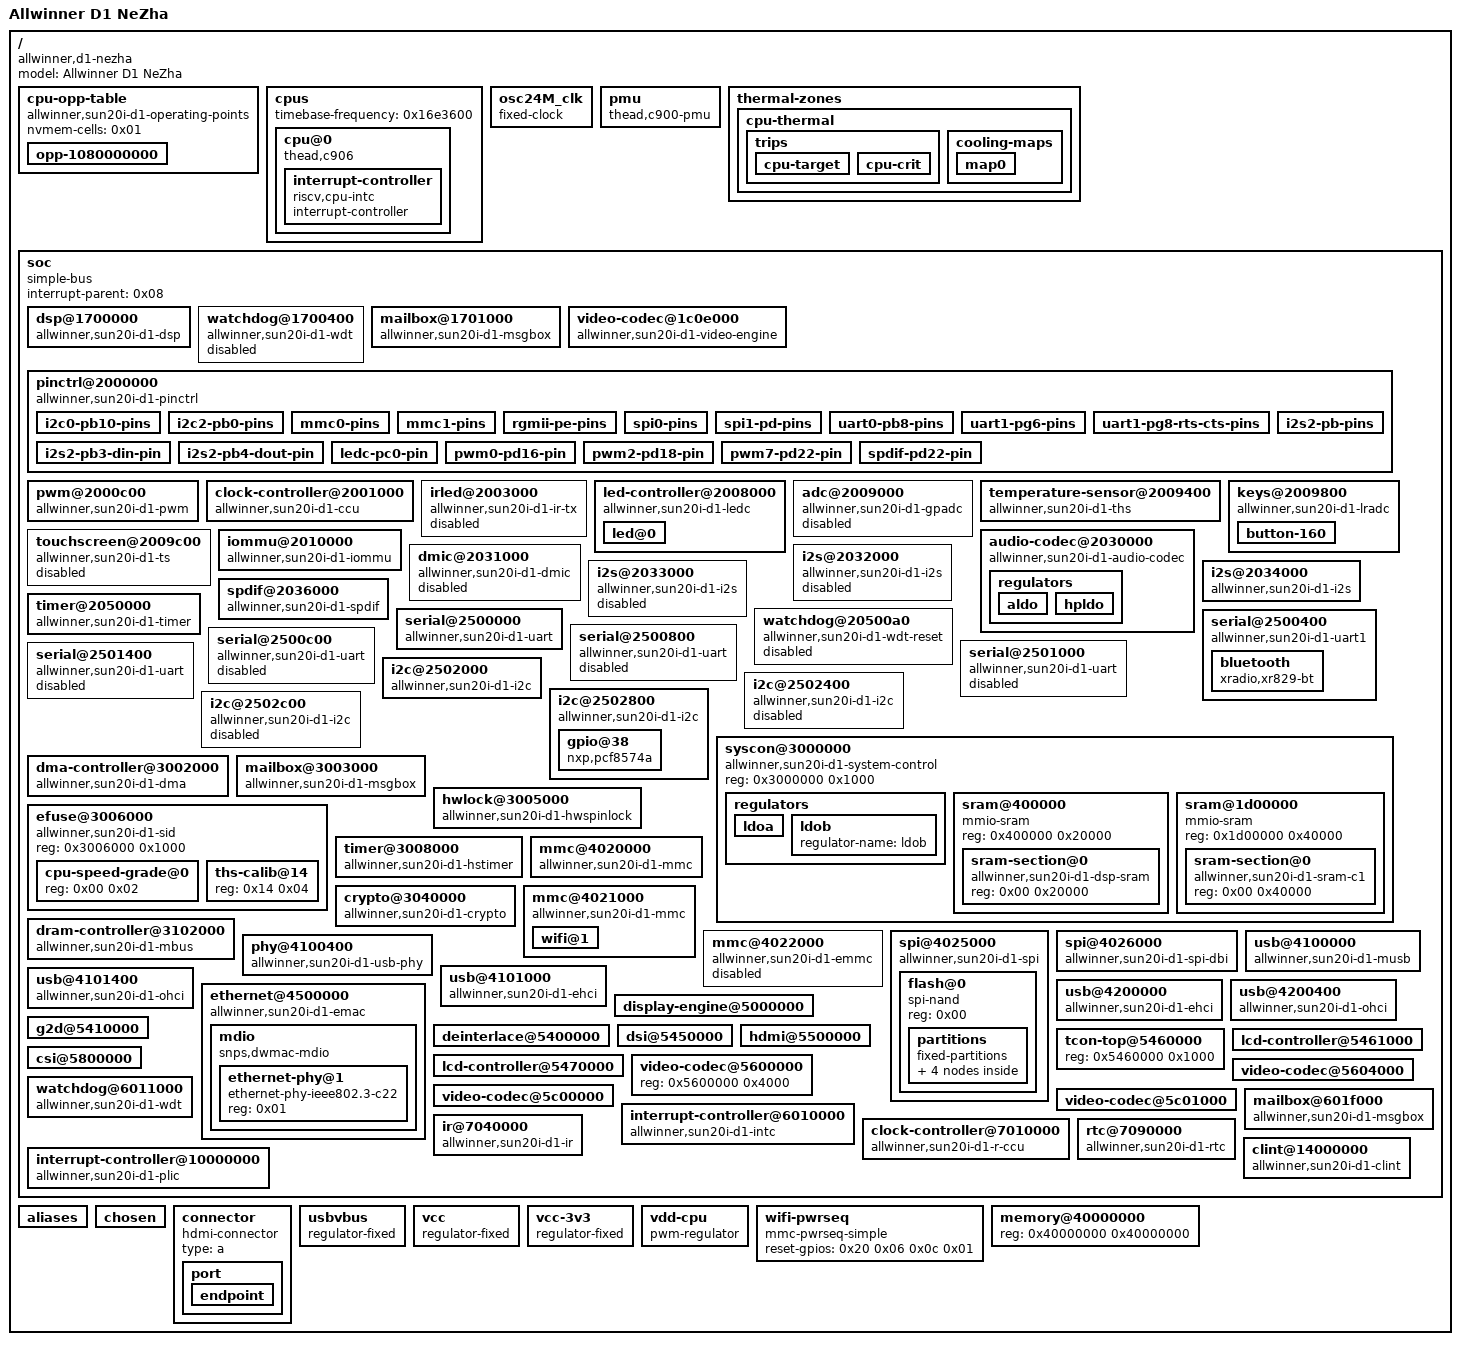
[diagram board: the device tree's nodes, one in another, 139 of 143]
/dts-v1/;

/ {
	#address-cells = <0x01>;
	#size-cells = <0x01>;
	model = "Allwinner D1 NeZha";
	compatible = "allwinner,d1-nezha", "allwinner,sun20i-d1";

	cpu-opp-table {
		compatible = "allwinner,sun20i-d1-operating-points", "allwinner,sun50i-h6-operating-points";
		nvmem-cells = <0x01>;
		phandle = <0x03>;

		opp-1080000000 {
			clock-latency-ns = <0x3b9b0>;
			opp-hz = <0x00 0x3c14dc00>;
			opp-microvolt-speed0 = <0x10c8e0>;
		};
	};

	cpus {
		#address-cells = <0x01>;
		#size-cells = <0x00>;
		timebase-frequency = <0x16e3600>;

		cpu@0 {
			compatible = "thead,c906", "riscv";
			device_type = "cpu";
			reg = <0x00>;
			clocks = <0x02 0x84>;
			clock-frequency = <0x16e3600>;
			#cooling-cells = <0x02>;
			d-cache-block-size = <0x40>;
			d-cache-sets = <0x100>;
			d-cache-size = <0x8000>;
			i-cache-block-size = <0x40>;
			i-cache-sets = <0x80>;
			i-cache-size = <0x8000>;
			mmu-type = "riscv,sv39";
			operating-points-v2 = <0x03>;
			riscv,isa = "rv64imafdc";
			cpu-supply = <0x04>;
			phandle = <0x07>;

			interrupt-controller {
				compatible = "riscv,cpu-intc";
				#address-cells = <0x00>;
				interrupt-controller;
				#interrupt-cells = <0x01>;
				phandle = <0x30>;
			};
		};
	};

	osc24M_clk {
		#clock-cells = <0x00>;
		compatible = "fixed-clock";
		clock-frequency = <0x16e3600>;
		clock-output-names = "osc24M";
		phandle = <0x0c>;
	};

	pmu {
		compatible = "thead,c900-pmu";
	};

	thermal-zones {

		cpu-thermal {
			polling-delay = <0x00>;
			polling-delay-passive = <0x00>;
			thermal-sensors = <0x05 0x00>;

			trips {

				cpu-target {
					hysteresis = <0xbb8>;
					temperature = <0x14c08>;
					type = "passive";
					phandle = <0x06>;
				};

				cpu-crit {
					hysteresis = <0x00>;
					temperature = <0x1adb0>;
					type = "critical";
				};
			};

			cooling-maps {

				map0 {
					trip = <0x06>;
					cooling-device = <0x07 0xffffffff 0xffffffff>;
				};
			};
		};
	};

	soc {
		compatible = "simple-bus";
		#address-cells = <0x01>;
		#size-cells = <0x01>;
		ranges;
		interrupt-parent = <0x08>;

		dsp@1700000 {
			compatible = "allwinner,sun20i-d1-dsp";
			reg = <0x1700000 0x400>;
			reg-names = "cfg";
			clocks = <0x02 0x83 0x02 0x82>;
			clock-names = "cfg", "dsp";
			resets = <0x02 0x3f 0x02 0x40 0x02 0x3e>;
			allwinner,sram = <0x09 0x01>;
			interrupts = <0x88 0x04 0x89 0x04>;
			interrupt-names = "dee", "pfe";
			mboxes = <0x0a 0x01 0x00 0x0b 0x02 0x01>;
			mbox-names = "rx", "tx";
		};

		watchdog@1700400 {
			compatible = "allwinner,sun20i-d1-wdt";
			reg = <0x1700400 0x20>;
			clocks = <0x0c>;
			interrupts = <0x8a 0x04>;
			status = "reserved";
		};

		mailbox@1701000 {
			compatible = "allwinner,sun20i-d1-msgbox";
			reg = <0x1701000 0x1000>;
			clocks = <0x02 0x27>;
			resets = <0x02 0x08>;
			interrupts = <0x8b 0x04 0x8c 0x04>;
			interrupt-names = "rx", "tx";
			#mbox-cells = <0x02>;
			phandle = <0x0b>;
		};

		video-codec@1c0e000 {
			compatible = "allwinner,sun20i-d1-video-engine";
			reg = <0x1c0e000 0x2000>;
			clocks = <0x02 0x24 0x02 0x23 0x02 0x31>;
			clock-names = "ahb", "mod", "ram";
			resets = <0x02 0x05>;
			allwinner,sram = <0x0d 0x01>;
			interconnects = <0x0e 0x04>;
			interconnect-names = "dma-mem";
			interrupts = <0x52 0x04>;
			iommus = <0x0f 0x00>;
		};

		pinctrl@2000000 {
			compatible = "allwinner,sun20i-d1-pinctrl";
			#address-cells = <0x00>;
			reg = <0x2000000 0x800>;
			clocks = <0x02 0x18 0x0c 0x10 0x00>;
			clock-names = "apb", "hosc", "losc";
			gpio-controller;
			#gpio-cells = <0x03>;
			interrupts = <0x55 0x04 0x57 0x04 0x59 0x04 0x5b 0x04 0x5d 0x04 0x5f 0x04>;
			interrupt-names = "pb", "pc", "pd", "pe", "pf", "pg";
			interrupt-controller;
			#interrupt-cells = <0x03>;
			vcc-pa-supply = <0x11>;
			vcc-pb-supply = <0x11>;
			vcc-pc-supply = <0x11>;
			vcc-pd-supply = <0x11>;
			vcc-pe-supply = <0x11>;
			vcc-pf-supply = <0x11>;
			vcc-pg-supply = <0x11>;
			phandle = <0x20>;

			i2c0-pb10-pins {
				pins = "PB10", "PB11";
				function = "i2c0";
				phandle = <0x21>;
			};

			i2c2-pb0-pins {
				pins = "PB0", "PB1";
				function = "i2c2";
				phandle = <0x22>;
			};

			mmc0-pins {
				pins = "PF0", "PF1", "PF2", "PF3", "PF4", "PF5";
				function = "mmc0";
				phandle = <0x23>;
			};

			mmc1-pins {
				pins = "PG0", "PG1", "PG2", "PG3", "PG4", "PG5";
				function = "mmc1";
				phandle = <0x25>;
			};

			rgmii-pe-pins {
				pins = "PE0", "PE1", "PE2", "PE3", "PE4", "PE5", "PE6", "PE7", "PE8", "PE9", "PE11", "PE12", "PE13", "PE14", "PE15";
				function = "emac";
				phandle = <0x2c>;
			};

			spi0-pins {
				pins = "PC2", "PC3", "PC4", "PC5", "PC6", "PC7";
				function = "spi0";
				phandle = <0x26>;
			};

			spi1-pd-pins {
				pins = "PD10", "PD11", "PD12", "PD13", "PD14", "PD15";
				function = "spi1";
				phandle = <0x27>;
			};

			uart0-pb8-pins {
				pins = "PB8", "PB9";
				function = "uart0";
				phandle = <0x1d>;
			};

			uart1-pg6-pins {
				pins = "PG6", "PG7";
				function = "uart1";
				phandle = <0x1e>;
			};

			uart1-pg8-rts-cts-pins {
				pins = "PG8", "PG9";
				function = "uart1";
				phandle = <0x1f>;
			};

			i2s2-pb-pins {
				pins = "PB5", "PB6", "PB7";
				function = "i2s2";
				phandle = <0x19>;
			};

			i2s2-pb3-din-pin {
				pins = "PB3";
				function = "i2s2_din";
				phandle = <0x1a>;
			};

			i2s2-pb4-dout-pin {
				pins = "PB4";
				function = "i2s2_dout";
				phandle = <0x1b>;
			};

			ledc-pc0-pin {
				pins = "PC0";
				function = "ledc";
				phandle = <0x15>;
			};

			pwm0-pd16-pin {
				pins = "PD16";
				function = "pwm";
				phandle = <0x12>;
			};

			pwm2-pd18-pin {
				pins = "PD18";
				function = "pwm";
				phandle = <0x13>;
			};

			pwm7-pd22-pin {
				pins = "PD22";
				function = "pwm";
			};

			spdif-pd22-pin {
				pins = "PD22";
				function = "spdif";
				phandle = <0x1c>;
			};
		};

		pwm@2000c00 {
			compatible = "allwinner,sun20i-d1-pwm";
			reg = <0x2000c00 0x400>;
			clocks = <0x02 0x2d 0x0c>;
			clock-names = "bus", "mod";
			resets = <0x02 0x0d>;
			interrupts = <0x22 0x04>;
			#pwm-cells = <0x03>;
			status = "okay";
			pinctrl-0 = <0x12 0x13>;
			pinctrl-names = "default";
			phandle = <0x31>;
		};

		clock-controller@2001000 {
			compatible = "allwinner,sun20i-d1-ccu";
			reg = <0x2001000 0x1000>;
			clocks = <0x0c 0x10 0x00 0x10 0x02>;
			clock-names = "hosc", "losc", "iosc";
			#clock-cells = <0x01>;
			#reset-cells = <0x01>;
			phandle = <0x02>;
		};

		irled@2003000 {
			compatible = "allwinner,sun20i-d1-ir-tx";
			reg = <0x2003000 0x400>;
			clocks = <0x02 0x4f 0x0c 0x02 0x4e>;
			clock-names = "bus", "pclk", "mclk";
			resets = <0x02 0x1f>;
			dmas = <0x14 0x0d>;
			dma-names = "tx";
			interrupts = <0x23 0x04>;
			status = "disabled";
		};

		led-controller@2008000 {
			compatible = "allwinner,sun20i-d1-ledc", "allwinner,sun50i-r329-ledc";
			reg = <0x2008000 0x400>;
			#address-cells = <0x01>;
			#size-cells = <0x00>;
			clocks = <0x02 0x7b 0x02 0x7a>;
			clock-names = "bus", "mod";
			resets = <0x02 0x3b>;
			dmas = <0x14 0x2a>;
			dma-names = "tx";
			interrupts = <0x24 0x04>;
			status = "okay";
			pinctrl-0 = <0x15>;
			pinctrl-names = "default";

			led@0 {
				reg = <0x00>;
				color = <0x09>;
				function = "indicator";
			};
		};

		adc@2009000 {
			compatible = "allwinner,sun20i-d1-gpadc";
			reg = <0x2009000 0x400>;
			clocks = <0x02 0x50>;
			resets = <0x02 0x20>;
			dmas = <0x14 0x0c>;
			dma-names = "rx";
			interrupts = <0x49 0x04>;
			status = "disabled";
		};

		temperature-sensor@2009400 {
			compatible = "allwinner,sun20i-d1-ths";
			reg = <0x2009400 0x400>;
			clocks = <0x02 0x51 0x0c>;
			clock-names = "bus", "mod";
			resets = <0x02 0x21>;
			interrupts = <0x4a 0x04>;
			nvmem-cells = <0x16>;
			nvmem-cell-names = "calibration";
			#thermal-sensor-cells = <0x00>;
			vref-supply = <0x17>;
			phandle = <0x05>;
		};

		keys@2009800 {
			compatible = "allwinner,sun20i-d1-lradc", "allwinner,sun50i-r329-lradc";
			reg = <0x2009800 0x400>;
			clocks = <0x02 0x68>;
			resets = <0x02 0x2f>;
			interrupts = <0x4d 0x04>;
			status = "okay";
			vref-supply = <0x17>;
			wakeup-source;

			button-160 {
				label = "OK";
				linux,code = <0x160>;
				channel = <0x00>;
				voltage = <0x27100>;
			};
		};

		touchscreen@2009c00 {
			compatible = "allwinner,sun20i-d1-ts";
			reg = <0x2009c00 0x400>;
			clocks = <0x02 0x80 0x02 0x7f>;
			clock-names = "bus", "mod";
			resets = <0x02 0x3d>;
			dmas = <0x14 0x0d>;
			dma-names = "rx";
			interrupts = <0x4e 0x04>;
			status = "disabled";
		};

		iommu@2010000 {
			compatible = "allwinner,sun20i-d1-iommu";
			reg = <0x2010000 0x10000>;
			clocks = <0x02 0x2e>;
			interrupts = <0x50 0x04>;
			#iommu-cells = <0x01>;
			phandle = <0x0f>;
		};

		audio-codec@2030000 {
			compatible = "allwinner,sun20i-d1-audio-codec";
			reg = <0x2030000 0x1000>;
			clocks = <0x02 0x60 0x02 0x5f 0x02 0x5e 0x0c 0x10 0x00>;
			clock-names = "bus", "adc", "dac", "hosc", "losc";
			resets = <0x02 0x27>;
			dmas = <0x14 0x07 0x14 0x07>;
			dma-names = "rx", "tx";
			interrupts = <0x29 0x04>;
			#sound-dai-cells = <0x00>;
			status = "okay";
			allwinner,routing = "Headphone Jack", "HPOUTL", "Headphone Jack", "HPOUTR", "LINEINL", "HPOUTL", "LINEINR", "HPOUTR", "MICIN3", "Headset Microphone", "Headset Microphone", "HBIAS";
			allwinner,widgets = "Microphone", "Headset Microphone", "Headphone", "Headphone Jack";
			avcc-supply = <0x17>;
			hpvcc-supply = <0x18>;
			vdd33-supply = <0x11>;

			regulators {

				aldo {
					regulator-name = "aldo";
					regulator-min-microvolt = <0x1b7740>;
					regulator-max-microvolt = <0x1b7740>;
					vdd33-supply = <0x11>;
					phandle = <0x17>;
				};

				hpldo {
					regulator-name = "hpldo";
					regulator-min-microvolt = <0x1b7740>;
					regulator-max-microvolt = <0x1b7740>;
					hpldoin-supply = <0x11>;
					phandle = <0x18>;
				};
			};
		};

		dmic@2031000 {
			compatible = "allwinner,sun20i-d1-dmic";
			reg = <0x2031000 0x400>;
			clocks = <0x02 0x5d 0x02 0x5c>;
			clock-names = "bus", "mod";
			resets = <0x02 0x26>;
			dmas = <0x14 0x08>;
			dma-names = "rx";
			interrupts = <0x28 0x04>;
			#sound-dai-cells = <0x00>;
			status = "disabled";
		};

		i2s@2032000 {
			compatible = "allwinner,sun20i-d1-i2s";
			reg = <0x2032000 0x1000>;
			clocks = <0x02 0x56 0x02 0x52>;
			clock-names = "apb", "mod";
			resets = <0x02 0x22>;
			dmas = <0x14 0x03 0x14 0x03>;
			dma-names = "rx", "tx";
			interrupts = <0x2a 0x04>;
			#sound-dai-cells = <0x00>;
			status = "disabled";
		};

		i2s@2033000 {
			compatible = "allwinner,sun20i-d1-i2s";
			reg = <0x2033000 0x1000>;
			clocks = <0x02 0x57 0x02 0x53>;
			clock-names = "apb", "mod";
			resets = <0x02 0x23>;
			dmas = <0x14 0x04 0x14 0x04>;
			dma-names = "rx", "tx";
			interrupts = <0x2b 0x04>;
			#sound-dai-cells = <0x00>;
			status = "disabled";
		};

		i2s@2034000 {
			compatible = "allwinner,sun20i-d1-i2s";
			reg = <0x2034000 0x1000>;
			clocks = <0x02 0x58 0x02 0x54>;
			clock-names = "apb", "mod";
			resets = <0x02 0x24>;
			dmas = <0x14 0x05 0x14 0x05>;
			dma-names = "rx", "tx";
			interrupts = <0x2c 0x04>;
			#sound-dai-cells = <0x00>;
			status = "okay";
			pinctrl-0 = <0x19 0x1a 0x1b>;
			pinctrl-names = "default";
		};

		spdif@2036000 {
			compatible = "allwinner,sun20i-d1-spdif";
			reg = <0x2036000 0x400>;
			clocks = <0x02 0x5b 0x02 0x5a 0x02 0x59>;
			clock-names = "apb", "rx", "tx";
			resets = <0x02 0x25>;
			dmas = <0x14 0x02 0x14 0x02>;
			dma-names = "rx", "tx";
			interrupts = <0x27 0x04>;
			#sound-dai-cells = <0x00>;
			status = "okay";
			pinctrl-0 = <0x1c>;
			pinctrl-names = "default";
		};

		timer@2050000 {
			compatible = "allwinner,sun20i-d1-timer", "allwinner,sun8i-a23-timer";
			reg = <0x2050000 0xa0>;
			clocks = <0x0c>;
			interrupts = <0x4b 0x04 0x4c 0x04>;
		};

		watchdog@20500a0 {
			compatible = "allwinner,sun20i-d1-wdt-reset", "allwinner,sun20i-d1-wdt";
			reg = <0x20500a0 0x20>;
			clocks = <0x0c>;
			interrupts = <0x4f 0x04>;
			status = "reserved";
		};

		serial@2500000 {
			compatible = "allwinner,sun20i-d1-uart", "snps,dw-apb-uart";
			reg = <0x2500000 0x400>;
			reg-io-width = <0x04>;
			reg-shift = <0x02>;
			clocks = <0x02 0x3e>;
			resets = <0x02 0x12>;
			dmas = <0x14 0x0e 0x14 0x0e>;
			dma-names = "rx", "tx";
			fifo-size = <0x40>;
			interrupts = <0x12 0x04>;
			status = "okay";
			pinctrl-0 = <0x1d>;
			pinctrl-names = "default";
		};

		serial@2500400 {
			compatible = "allwinner,sun20i-d1-uart1", "allwinner,sun20i-d1-uart", "snps,dw-apb-uart";
			reg = <0x2500400 0x400>;
			reg-io-width = <0x04>;
			reg-shift = <0x02>;
			clocks = <0x02 0x3f>;
			resets = <0x02 0x13>;
			dmas = <0x14 0x0f 0x14 0x0f>;
			dma-names = "rx", "tx";
			fifo-size = <0x100>;
			interrupts = <0x13 0x04>;
			status = "okay";
			pinctrl-0 = <0x1e 0x1f>;
			pinctrl-names = "default";

			bluetooth {
				compatible = "xradio,xr829-bt";
				device-wakeup-gpios = <0x20 0x06 0x10 0x01>;
				interrupts-extended = <0x20 0x06 0x11 0x08>;
				interrupt-names = "wakeup";
				reset-gpios = <0x20 0x06 0x12 0x01>;
			};
		};

		serial@2500800 {
			compatible = "allwinner,sun20i-d1-uart", "snps,dw-apb-uart";
			reg = <0x2500800 0x400>;
			reg-io-width = <0x04>;
			reg-shift = <0x02>;
			clocks = <0x02 0x40>;
			resets = <0x02 0x14>;
			dmas = <0x14 0x10 0x14 0x10>;
			dma-names = "rx", "tx";
			fifo-size = <0x100>;
			interrupts = <0x14 0x04>;
			status = "disabled";
		};

		serial@2500c00 {
			compatible = "allwinner,sun20i-d1-uart", "snps,dw-apb-uart";
			reg = <0x2500c00 0x400>;
			reg-io-width = <0x04>;
			reg-shift = <0x02>;
			clocks = <0x02 0x41>;
			resets = <0x02 0x15>;
			dmas = <0x14 0x11 0x14 0x11>;
			dma-names = "rx", "tx";
			fifo-size = <0x100>;
			interrupts = <0x15 0x04>;
			status = "disabled";
		};

		serial@2501000 {
			compatible = "allwinner,sun20i-d1-uart", "snps,dw-apb-uart";
			reg = <0x2501000 0x400>;
			reg-io-width = <0x04>;
			reg-shift = <0x02>;
			clocks = <0x02 0x42>;
			resets = <0x02 0x16>;
			dmas = <0x14 0x12 0x14 0x12>;
			dma-names = "rx", "tx";
			fifo-size = <0x100>;
			interrupts = <0x16 0x04>;
			status = "disabled";
		};

		serial@2501400 {
			compatible = "allwinner,sun20i-d1-uart", "snps,dw-apb-uart";
			reg = <0x2501400 0x400>;
			reg-io-width = <0x04>;
			reg-shift = <0x02>;
			clocks = <0x02 0x43>;
			resets = <0x02 0x17>;
			dmas = <0x14 0x13 0x14 0x13>;
			dma-names = "rx", "tx";
			fifo-size = <0x100>;
			interrupts = <0x17 0x04>;
			status = "disabled";
		};

		i2c@2502000 {
			compatible = "allwinner,sun20i-d1-i2c", "allwinner,sun6i-a31-i2c";
			reg = <0x2502000 0x400>;
			#address-cells = <0x01>;
			#size-cells = <0x00>;
			clocks = <0x02 0x44>;
			resets = <0x02 0x18>;
			dmas = <0x14 0x2b 0x14 0x2b>;
			dma-names = "rx", "tx";
			interrupts = <0x19 0x04>;
			status = "okay";
			pinctrl-0 = <0x21>;
			pinctrl-names = "default";
		};

		i2c@2502400 {
			compatible = "allwinner,sun20i-d1-i2c", "allwinner,sun6i-a31-i2c";
			reg = <0x2502400 0x400>;
			#address-cells = <0x01>;
			#size-cells = <0x00>;
			clocks = <0x02 0x45>;
			resets = <0x02 0x19>;
			dmas = <0x14 0x2c 0x14 0x2c>;
			dma-names = "rx", "tx";
			interrupts = <0x1a 0x04>;
			status = "disabled";
		};

		i2c@2502800 {
			compatible = "allwinner,sun20i-d1-i2c", "allwinner,sun6i-a31-i2c";
			reg = <0x2502800 0x400>;
			#address-cells = <0x01>;
			#size-cells = <0x00>;
			clocks = <0x02 0x46>;
			resets = <0x02 0x1a>;
			dmas = <0x14 0x2d 0x14 0x2d>;
			dma-names = "rx", "tx";
			interrupts = <0x1b 0x04>;
			status = "okay";
			pinctrl-0 = <0x22>;
			pinctrl-names = "default";

			gpio@38 {
				compatible = "nxp,pcf8574a";
				#address-cells = <0x00>;
				reg = <0x38>;
				gpio-controller;
				#gpio-cells = <0x02>;
				interrupts-extended = <0x20 0x01 0x02 0x08>;
				interrupt-controller;
				#interrupt-cells = <0x02>;
			};
		};

		i2c@2502c00 {
			compatible = "allwinner,sun20i-d1-i2c", "allwinner,sun6i-a31-i2c";
			reg = <0x2502c00 0x400>;
			#address-cells = <0x01>;
			#size-cells = <0x00>;
			clocks = <0x02 0x47>;
			resets = <0x02 0x1b>;
			dmas = <0x14 0x2e 0x14 0x2e>;
			dma-names = "rx", "tx";
			interrupts = <0x1c 0x04>;
			status = "disabled";
		};

		syscon@3000000 {
			compatible = "allwinner,sun20i-d1-system-control";
			reg = <0x3000000 0x1000>;
			#address-cells = <0x01>;
			#size-cells = <0x01>;
			ranges;
			phandle = <0x2b>;

			regulators {

				ldoa {
					regulator-name = "ldoa";
					regulator-always-on;
					regulator-min-microvolt = <0x1b7740>;
					regulator-max-microvolt = <0x1b7740>;
					ldo-in-supply = <0x11>;
				};

				ldob {
					regulator-name = "ldob";
				};
			};

			sram@400000 {
				compatible = "mmio-sram";
				reg = <0x400000 0x20000>;
				#address-cells = <0x01>;
				#size-cells = <0x01>;
				ranges = <0x00 0x400000 0x20000>;

				sram-section@0 {
					compatible = "allwinner,sun20i-d1-dsp-sram";
					reg = <0x00 0x20000>;
					phandle = <0x09>;
				};
			};

			sram@1d00000 {
				compatible = "mmio-sram";
				reg = <0x1d00000 0x40000>;
				#address-cells = <0x01>;
				#size-cells = <0x01>;
				ranges = <0x00 0x1d00000 0x40000>;

				sram-section@0 {
					compatible = "allwinner,sun20i-d1-sram-c1", "allwinner,sun4i-a10-sram-c1";
					reg = <0x00 0x40000>;
					phandle = <0x0d>;
				};
			};
		};

		dma-controller@3002000 {
			compatible = "allwinner,sun20i-d1-dma";
			reg = <0x3002000 0x1000>;
			clocks = <0x02 0x25 0x02 0x30>;
			clock-names = "bus", "mbus";
			resets = <0x02 0x06>;
			#dma-cells = <0x01>;
			dma-channels = <0x10>;
			dma-requests = <0x30>;
			interrupts = <0x42 0x04 0x8e 0x04>;
			phandle = <0x14>;
		};

		mailbox@3003000 {
			compatible = "allwinner,sun20i-d1-msgbox";
			reg = <0x3003000 0x1000>;
			clocks = <0x02 0x26>;
			resets = <0x02 0x07>;
			interrupts = <0x65 0x04 0x66 0x04>;
			interrupt-names = "rx", "tx";
			#mbox-cells = <0x02>;
		};

		hwlock@3005000 {
			compatible = "allwinner,sun20i-d1-hwspinlock", "allwinner,sun6i-a31-hwspinlock";
			reg = <0x3005000 0x1000>;
			clocks = <0x02 0x29>;
			resets = <0x02 0x0a>;
			interrupts = <0x46 0x04>;
		};

		efuse@3006000 {
			compatible = "allwinner,sun20i-d1-sid", "allwinner,sun50i-a64-sid";
			reg = <0x3006000 0x1000>;
			#address-cells = <0x01>;
			#size-cells = <0x01>;

			cpu-speed-grade@0 {
				reg = <0x00 0x02>;
				phandle = <0x01>;
			};

			ths-calib@14 {
				reg = <0x14 0x04>;
				phandle = <0x16>;
			};
		};

		timer@3008000 {
			compatible = "allwinner,sun20i-d1-hstimer", "allwinner,sun50i-h6-hstimer";
			reg = <0x3008000 0x1000>;
			clocks = <0x02 0x2a>;
			resets = <0x02 0x0b>;
			interrupts = <0x47 0x04 0x48 0x04>;
		};

		crypto@3040000 {
			compatible = "allwinner,sun20i-d1-crypto";
			reg = <0x3040000 0x800>;
			clocks = <0x02 0x22 0x02 0x21 0x02 0x32>;
			clock-names = "bus", "mod", "ram";
			resets = <0x02 0x04>;
			interrupts = <0x44 0x04>;
		};

		dram-controller@3102000 {
			compatible = "allwinner,sun20i-d1-mbus";
			reg = <0x3102000 0x200000>;
			#address-cells = <0x01>;
			#size-cells = <0x01>;
			clocks = <0x02 0x37 0x02 0x2f 0x02 0x1a>;
			clock-names = "bus", "dram", "mbus";
			dma-ranges = <0x00 0x40000000 0x80000000>;
			#interconnect-cells = <0x01>;
			interrupts = <0x3b 0x04>;
			phandle = <0x0e>;
		};

		mmc@4020000 {
			compatible = "allwinner,sun20i-d1-mmc";
			reg = <0x4020000 0x1000>;
			#address-cells = <0x01>;
			#size-cells = <0x00>;
			clocks = <0x02 0x3b 0x02 0x38>;
			clock-names = "ahb", "mmc";
			resets = <0x02 0x0f>;
			reset-names = "ahb";
			cap-sd-highspeed;
			interrupts = <0x38 0x04>;
			max-frequency = <0x8f0d180>;
			no-mmc;
			status = "okay";
			bus-width = <0x04>;
			cd-gpios = <0x20 0x05 0x06 0x00>;
			disable-wp;
			vmmc-supply = <0x11>;
			vqmmc-supply = <0x11>;
			pinctrl-0 = <0x23>;
			pinctrl-names = "default";
		};

		mmc@4021000 {
			compatible = "allwinner,sun20i-d1-mmc";
			reg = <0x4021000 0x1000>;
			#address-cells = <0x01>;
			#size-cells = <0x00>;
			clocks = <0x02 0x3c 0x02 0x39>;
			clock-names = "ahb", "mmc";
			resets = <0x02 0x10>;
			reset-names = "ahb";
			cap-sd-highspeed;
			interrupts = <0x39 0x04>;
			max-frequency = <0x8f0d180>;
			no-mmc;
			status = "okay";
			bus-width = <0x04>;
			mmc-pwrseq = <0x24>;
			non-removable;
			vmmc-supply = <0x11>;
			vqmmc-supply = <0x11>;
			pinctrl-0 = <0x25>;
			pinctrl-names = "default";

			wifi@1 {
				reg = <0x01>;
				host-wake-gpios = <0x20 0x06 0x0a 0x01>;
			};
		};

		mmc@4022000 {
			compatible = "allwinner,sun20i-d1-emmc";
			reg = <0x4022000 0x1000>;
			#address-cells = <0x01>;
			#size-cells = <0x00>;
			clocks = <0x02 0x3d 0x02 0x3a>;
			clock-names = "ahb", "mmc";
			resets = <0x02 0x11>;
			reset-names = "ahb";
			cap-mmc-highspeed;
			interrupts = <0x3a 0x04>;
			max-frequency = <0x8f0d180>;
			mmc-ddr-1_8v;
			mmc-ddr-3_3v;
			no-sd;
			no-sdio;
			status = "disabled";
		};

		spi@4025000 {
			compatible = "allwinner,sun20i-d1-spi", "allwinner,sun50i-r329-spi";
			reg = <0x4025000 0x1000>;
			#address-cells = <0x01>;
			#size-cells = <0x00>;
			clocks = <0x02 0x4a 0x02 0x48>;
			clock-names = "ahb", "mod";
			resets = <0x02 0x1c>;
			dmas = <0x14 0x16 0x14 0x16>;
			dma-names = "rx", "tx";
			interrupts = <0x1f 0x04>;
			num-cs = <0x01>;
			status = "okay";
			pinctrl-0 = <0x26>;
			pinctrl-names = "default";

			flash@0 {
				compatible = "spi-nand";
				reg = <0x00>;

				partitions {
					compatible = "fixed-partitions";
					#address-cells = <0x01>;
					#size-cells = <0x01>;

					partition@0 {
						label = "boot0";
						reg = <0x00 0x100000>;
					};

					partition@100000 {
						label = "uboot";
						reg = <0x100000 0x300000>;
					};

					partition@400000 {
						label = "secure_storage";
						reg = <0x400000 0x100000>;
					};

					partition@500000 {
						label = "sys";
						reg = <0x500000 0xfb00000>;
					};
				};
			};
		};

		spi@4026000 {
			compatible = "allwinner,sun20i-d1-spi-dbi", "allwinner,sun50i-r329-spi-dbi", "allwinner,sun50i-r329-spi";
			reg = <0x4026000 0x1000>;
			#address-cells = <0x01>;
			#size-cells = <0x00>;
			clocks = <0x02 0x4b 0x02 0x49>;
			clock-names = "ahb", "mod";
			resets = <0x02 0x1d>;
			dmas = <0x14 0x17 0x14 0x17>;
			dma-names = "rx", "tx";
			interrupts = <0x20 0x04>;
			num-cs = <0x01>;
			status = "okay";
			pinctrl-0 = <0x27>;
			pinctrl-names = "default";
		};

		usb@4100000 {
			compatible = "allwinner,sun20i-d1-musb", "allwinner,sun8i-a33-musb";
			reg = <0x4100000 0x400>;
			clocks = <0x02 0x67>;
			resets = <0x02 0x2e>;
			dmas = <0x14 0x1e 0x14 0x1e 0x14 0x1f 0x14 0x1f 0x14 0x20 0x14 0x20 0x14 0x21 0x14 0x21 0x14 0x22 0x14 0x22>;
			dma-names = "ep1_rx", "ep1_tx", "ep2_rx", "ep2_tx", "ep3_rx", "ep3_tx", "ep4_rx", "ep4_tx", "ep5_rx", "ep5_tx";
			extcon = <0x28 0x00>;
			interrupts = <0x2d 0x04>;
			interrupt-names = "mc";
			phys = <0x28 0x00>;
			phy-names = "usb";
			status = "okay";
			dr_mode = "otg";
		};

		phy@4100400 {
			compatible = "allwinner,sun20i-d1-usb-phy";
			reg = <0x4100400 0x100 0x4101800 0x100 0x4200800 0x100>;
			reg-names = "phy_ctrl", "pmu0", "pmu1";
			clocks = <0x0c 0x0c>;
			clock-names = "usb0_phy", "usb1_phy";
			resets = <0x02 0x28 0x02 0x29>;
			reset-names = "usb0_reset", "usb1_reset";
			#phy-cells = <0x01>;
			status = "okay";
			usb0_id_det-gpios = <0x20 0x03 0x15 0x01>;
			usb0_vbus_det-gpios = <0x20 0x03 0x14 0x00>;
			usb0_vbus-supply = <0x29>;
			usb1_vbus-supply = <0x2a>;
			phandle = <0x28>;
		};

		usb@4101000 {
			compatible = "allwinner,sun20i-d1-ehci", "generic-ehci";
			reg = <0x4101000 0x100>;
			clocks = <0x02 0x63 0x02 0x65 0x02 0x61>;
			resets = <0x02 0x2a 0x02 0x2c>;
			interrupts = <0x2e 0x04>;
			phys = <0x28 0x00>;
			phy-names = "usb";
			status = "okay";
		};

		usb@4101400 {
			compatible = "allwinner,sun20i-d1-ohci", "generic-ohci";
			reg = <0x4101400 0x100>;
			clocks = <0x02 0x63 0x02 0x61>;
			resets = <0x02 0x2a>;
			interrupts = <0x2f 0x04>;
			phys = <0x28 0x00>;
			phy-names = "usb";
			status = "okay";
		};

		usb@4200000 {
			compatible = "allwinner,sun20i-d1-ehci", "generic-ehci";
			reg = <0x4200000 0x100>;
			clocks = <0x02 0x64 0x02 0x66 0x02 0x62>;
			resets = <0x02 0x2b 0x02 0x2d>;
			interrupts = <0x31 0x04>;
			phys = <0x28 0x01>;
			phy-names = "usb";
			status = "okay";
		};

		usb@4200400 {
			compatible = "allwinner,sun20i-d1-ohci", "generic-ohci";
			reg = <0x4200400 0x100>;
			clocks = <0x02 0x64 0x02 0x62>;
			resets = <0x02 0x2b>;
			interrupts = <0x32 0x04>;
			phys = <0x28 0x01>;
			phy-names = "usb";
			status = "okay";
		};

		ethernet@4500000 {
			compatible = "allwinner,sun20i-d1-emac", "allwinner,sun50i-a64-emac";
			reg = <0x4500000 0x10000>;
			clocks = <0x02 0x4d>;
			clock-names = "stmmaceth";
			resets = <0x02 0x1e>;
			reset-names = "stmmaceth";
			interrupts = <0x3e 0x04>;
			interrupt-names = "macirq";
			syscon = <0x2b>;
			status = "okay";
			pinctrl-0 = <0x2c>;
			pinctrl-names = "default";
			phy-handle = <0x2d>;
			phy-mode = "rgmii-id";
			phy-supply = <0x11>;

			mdio {
				compatible = "snps,dwmac-mdio";
				#address-cells = <0x01>;
				#size-cells = <0x00>;

				ethernet-phy@1 {
					compatible = "ethernet-phy-ieee802.3-c22";
					reg = <0x01>;
					phandle = <0x2d>;
				};
			};
		};

		display-engine@5000000 {
			reg = <0x5000000 0x400000>;
			interrupts = <0x67 0x04>;
			interconnects = <0x0e 0x0b>;
			interconnect-names = "dma-mem";
			iommus = <0x0f 0x02>;
		};

		deinterlace@5400000 {
			reg = <0x5400000 0x10000>;
			interconnects = <0x0e 0x0a>;
			interconnect-names = "dma-mem";
			interrupts = <0x68 0x04>;
			iommus = <0x0f 0x04>;
		};

		g2d@5410000 {
			reg = <0x5410000 0x40000>;
			interconnects = <0x0e 0x09>;
			interconnect-names = "dma-mem";
			interrupts = <0x69 0x04>;
			iommus = <0x0f 0x03>;
		};

		dsi@5450000 {
			reg = <0x5450000 0x2000>;
			interrupts = <0x6c 0x04>;
		};

		tcon-top@5460000 {
			reg = <0x5460000 0x1000>;
		};

		lcd-controller@5461000 {
			reg = <0x5461000 0x1000>;
			interrupts = <0x6a 0x04>;
		};

		lcd-controller@5470000 {
			reg = <0x5470000 0x1000>;
			interrupts = <0x6b 0x04>;
		};

		hdmi@5500000 {
			reg = <0x5500000 0x100000>;
			interrupts = <0x6d 0x04>;
		};

		video-codec@5600000 {
			reg = <0x5600000 0x4000>;
		};

		video-codec@5604000 {
			reg = <0x5604000 0x4000>;
			interrupts = <0x6e 0x04>;
		};

		csi@5800000 {
			reg = <0x5800000 0x400000>;
			interrupts = <0x6f 0x04 0x70 0x04 0x74 0x04 0x7a 0x04>;
			interconnects = <0x0e 0x07>;
			interconnect-names = "dma-mem";
			iommus = <0x0f 0x01>;
		};

		video-codec@5c00000 {
			reg = <0x5c00000 0x1000>;
			interconnects = <0x0e 0x06>;
			interconnect-names = "dma-mem";
		};

		video-codec@5c01000 {
			reg = <0x5c01000 0x1000>;
			interrupts = <0x7b 0x04>;
		};

		interrupt-controller@6010000 {
			compatible = "allwinner,sun20i-d1-intc";
			reg = <0x6010000 0x100>;
			#address-cells = <0x00>;
			clocks = <0x02 0x86>;
			resets = <0x02 0x41>;
			interrupt-parent = <0x2e>;
			interrupt-controller;
			#interrupt-cells = <0x02>;
			phandle = <0x08>;
		};

		watchdog@6011000 {
			compatible = "allwinner,sun20i-d1-wdt";
			reg = <0x6011000 0x20>;
			clocks = <0x0c>;
			interrupts = <0x93 0x04>;
		};

		mailbox@601f000 {
			compatible = "allwinner,sun20i-d1-msgbox";
			reg = <0x601f000 0x1000>;
			clocks = <0x02 0x28>;
			resets = <0x02 0x09>;
			interrupts = <0x90 0x04 0x91 0x04>;
			interrupt-names = "rx", "tx";
			#mbox-cells = <0x02>;
			phandle = <0x0a>;
		};

		clock-controller@7010000 {
			compatible = "allwinner,sun20i-d1-r-ccu";
			reg = <0x7010000 0x400>;
			clocks = <0x0c 0x10 0x00 0x10 0x02 0x02 0x06>;
			clock-names = "hosc", "losc", "iosc", "pll-periph";
			#clock-cells = <0x01>;
			#reset-cells = <0x01>;
			interrupts = <0x40 0x04>;
			phandle = <0x2f>;
		};

		ir@7040000 {
			compatible = "allwinner,sun20i-d1-ir", "allwinner,sun6i-a31-ir";
			reg = <0x7040000 0x400>;
			clocks = <0x2f 0x06 0x2f 0x05>;
			clock-names = "apb", "ir";
			resets = <0x2f 0x03>;
			interrupts = <0xa7 0x04>;
		};

		rtc@7090000 {
			compatible = "allwinner,sun20i-d1-rtc", "allwinner,sun50i-r329-rtc";
			reg = <0x7090000 0x400>;
			clocks = <0x2f 0x07 0x0c 0x2f 0x00>;
			clock-names = "bus", "hosc", "ahb";
			#clock-cells = <0x01>;
			interrupts = <0xa0 0x04>;
			phandle = <0x10>;
		};

		interrupt-controller@10000000 {
			compatible = "allwinner,sun20i-d1-plic", "thead,c900-plic";
			reg = <0x10000000 0x4000000>;
			#address-cells = <0x00>;
			interrupts-extended = <0x30 0x0b 0x30 0x09>;
			interrupt-controller;
			#interrupt-cells = <0x01>;
			riscv,ndev = <0xb0>;
			phandle = <0x2e>;
		};

		clint@14000000 {
			compatible = "allwinner,sun20i-d1-clint", "sifive,clint0";
			reg = <0x14000000 0xc000>;
			reg-io-width = <0x04>;
			interrupts-extended = <0x30 0x03 0x30 0x07>;
		};
	};

	aliases {
		ethernet0 = "/soc/ethernet@4500000";
		mmc0 = "/soc/mmc@4020000";
		mmc1 = "/soc/mmc@4021000";
		mmc2 = "/soc/mmc@4022000";
		serial0 = "/soc/serial@2500000";
		spi0 = "/soc/spi@4025000";
	};

	chosen {
		stdout-path = "serial0:115200n8";
		bootargs = "earlycon=sbi";
	};

	connector {
		compatible = "hdmi-connector";
		type = "a";

		port {

			endpoint {
			};
		};
	};

	usbvbus {
		compatible = "regulator-fixed";
		regulator-name = "usbvbus";
		regulator-min-microvolt = <0x4c4b40>;
		regulator-max-microvolt = <0x4c4b40>;
		gpio = <0x20 0x03 0x13 0x00>;
		enable-active-high;
		vin-supply = <0x2a>;
		phandle = <0x29>;
	};

	vcc {
		compatible = "regulator-fixed";
		regulator-name = "vcc";
		regulator-min-microvolt = <0x4c4b40>;
		regulator-max-microvolt = <0x4c4b40>;
		phandle = <0x2a>;
	};

	vcc-3v3 {
		compatible = "regulator-fixed";
		regulator-name = "vcc-3v3";
		regulator-min-microvolt = <0x325aa0>;
		regulator-max-microvolt = <0x325aa0>;
		vin-supply = <0x2a>;
		phandle = <0x11>;
	};

	vdd-cpu {
		compatible = "pwm-regulator";
		pwms = <0x31 0x00 0xc350 0x00>;
		pwm-supply = <0x2a>;
		regulator-name = "vdd-cpu";
		regulator-min-microvolt = <0xc5c10>;
		regulator-max-microvolt = <0x11b340>;
		phandle = <0x04>;
	};

	wifi-pwrseq {
		compatible = "mmc-pwrseq-simple";
		reset-gpios = <0x20 0x06 0x0c 0x01>;
		phandle = <0x24>;
	};

	memory@40000000 {
		device_type = "memory";
		reg = <0x40000000 0x40000000>;
	};
};
